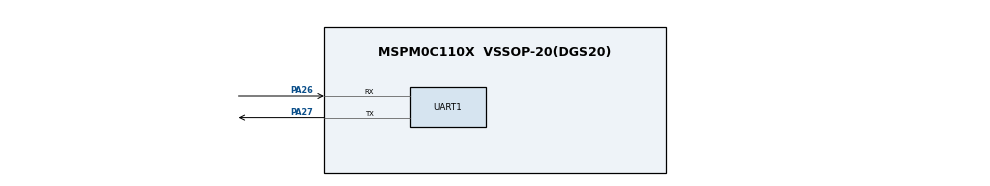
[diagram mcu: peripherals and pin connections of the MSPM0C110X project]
// @cliArgs --device "MSPM0C110X" --package "VSSOP-20(DGS20)" --part "Default"
// @cliArgs --board /ti/boards/LP_MSPM0C1104 --rtos nortos

/**
 * Import the modules used in this configuration.
 */
const UART   = scripting.addModule("/ti/driverlib/UART", {}, false);
const UART1  = UART.addInstance();

/**
 * Write custom configuration values to the imported modules.
 */

UART1.$name = "UART_0";
UART1.profile = "CONFIG_PROFILE_1";
UART1.peripheral.$assign = "UART0";
UART1.targetBaudRate = 9600;
UART1.enableInternalLoopback = false;
UART1.enabledInterrupts = ["RX"];
UART1.enableFIFO= false;

UART1.peripheral.txPin.$assign = "PA27";
UART1.peripheral.rxPin.$assign = "PA26";
